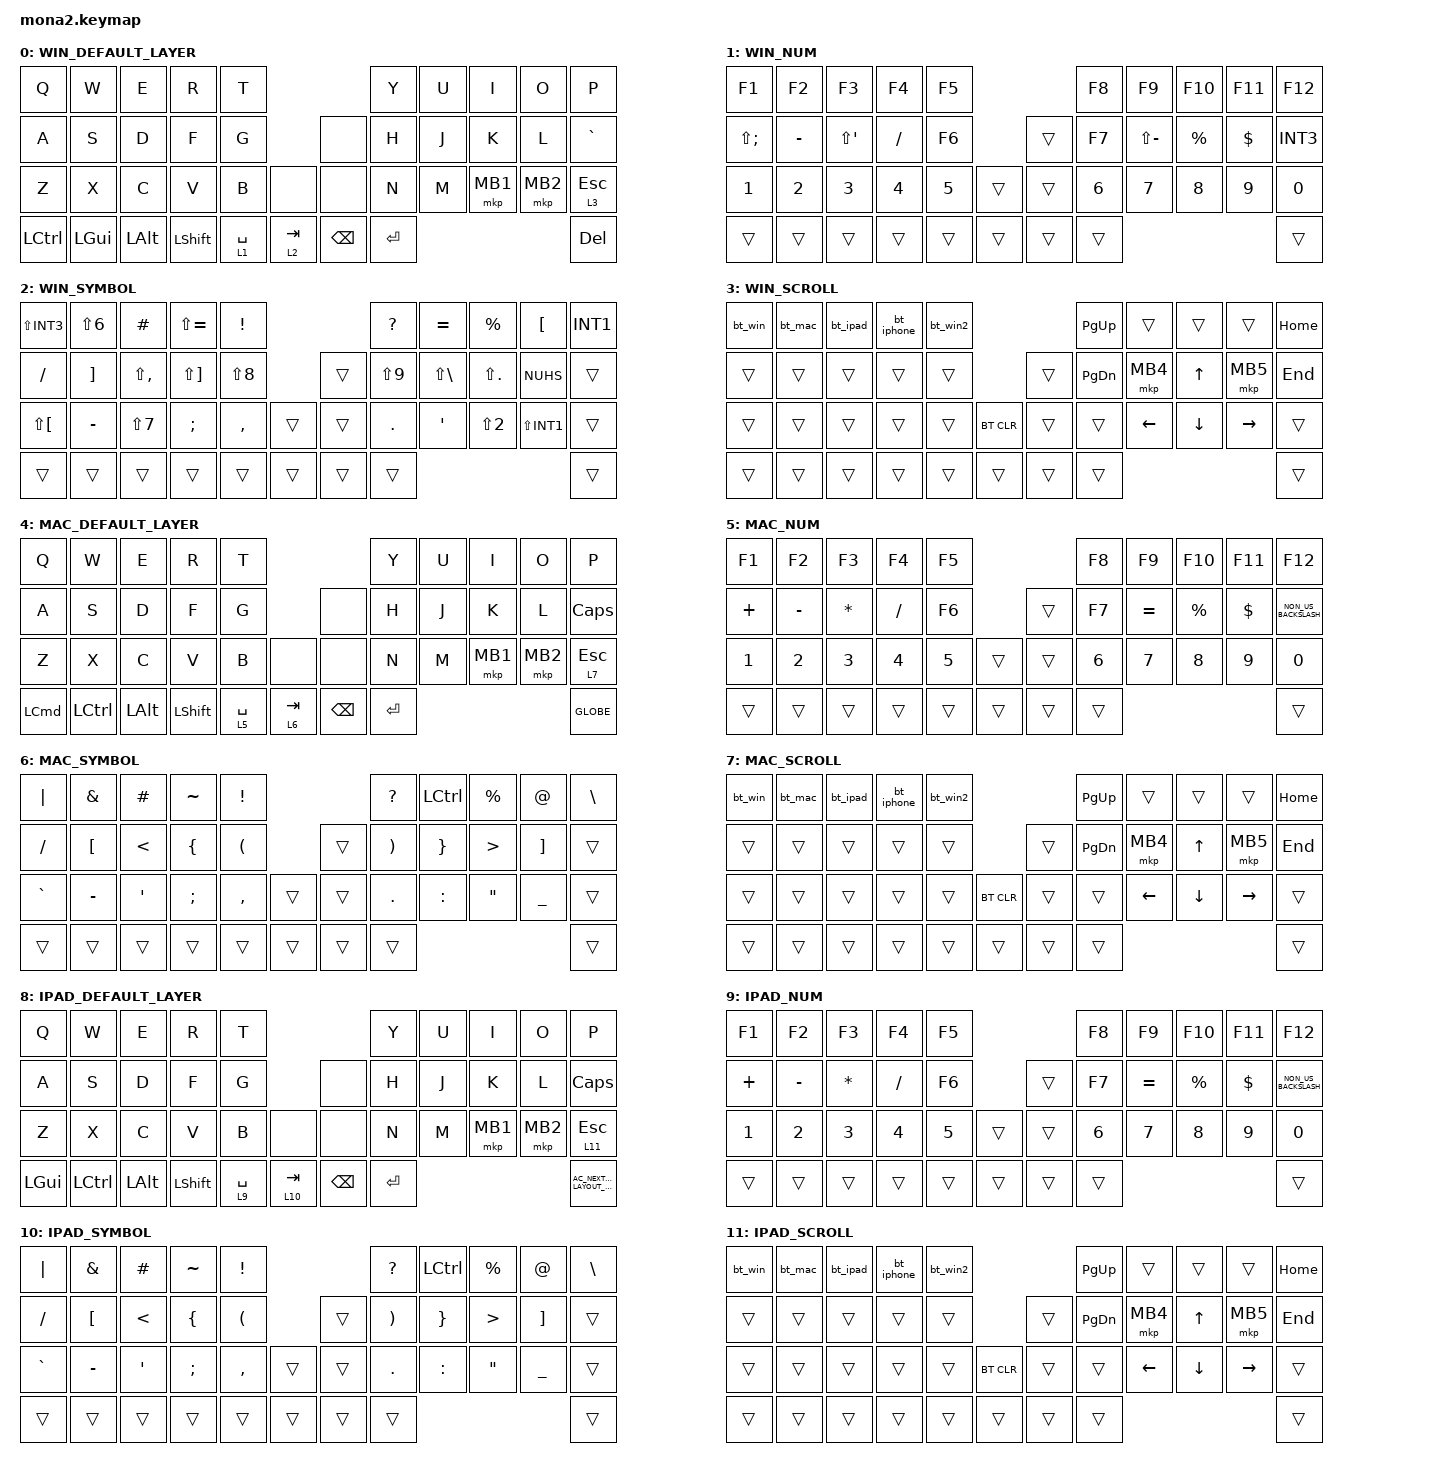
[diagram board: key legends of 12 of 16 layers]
#define ZMK_POINTING_DEFAULT_SCRL_VAL 300   // マウスホイール

#include <input/processors.dtsi>
#include <dt-bindings/zmk/input_transform.h>
#include <zephyr/dt-bindings/input/input-event-codes.h>
#include <behaviors.dtsi>
#include <dt-bindings/zmk/bt.h>
#include <dt-bindings/zmk/keys.h>
#include <dt-bindings/zmk/pointing.h>

#define MOUSE 0
#define SCROLL 3
#define NUM 2

&mt {
    flavor = "balanced";
    quick-tap-ms = <300>;
};

&lt {
    flavor = "balanced";
    quick-tap-ms = <300>;
};

/ {
    behaviors {
        scroll_up_down: behavior_sensor_rotate_mouse_wheel_up_down {
            compatible = "zmk,behavior-sensor-rotate";
            #sensor-binding-cells = <0>;
            bindings = <&msc SCRL_UP>, <&msc SCRL_DOWN>;

            tap-ms = <20>;
        };
    };

    combos { compatible = "zmk,combos"; };

    macros {
        bt_win: bt_win {
            compatible = "zmk,behavior-macro";
            #binding-cells = <0>;
            bindings = <&bt BT_SEL 0>, <&macro_wait_time 200>, <&to 0>;

            label = "BT_WIN";
        };

        bt_mac: bt_mac {
            compatible = "zmk,behavior-macro";
            #binding-cells = <0>;
            bindings = <&bt BT_SEL 1>, <&macro_wait_time 200>, <&to 4>;

            label = "BT_MAC";
        };

        bt_ipad: bt_ipad {
            compatible = "zmk,behavior-macro";
            #binding-cells = <0>;
            bindings = <&bt BT_SEL 2>, <&macro_wait_time 200>, <&to 8>;

            label = "BT_IPAD";
        };

        bt_iphone: bt_iphone {
            compatible = "zmk,behavior-macro";
            #binding-cells = <0>;
            bindings = <&bt BT_SEL 3>, <&macro_wait_time 200>, <&to 12>;

            label = "BT_IPHONE";
        };

        bt_win2: bt_win2 {
            compatible = "zmk,behavior-macro";
            #binding-cells = <0>;
            bindings = <&bt BT_SEL 4>, <&macro_wait_time 200>, <&to 0>;

            label = "BT_WIN2";
        };
    };

    keymap {
        compatible = "zmk,keymap";

        WIN_DEFAULT_LAYER {
            bindings = <
&kp Q      &kp W         &kp E         &kp R           &kp T                                    &kp Y      &kp U  &kp I     &kp O     &kp P
&kp A      &kp S         &kp D         &kp F           &kp G                     &none          &kp H      &kp J  &kp K     &kp L     &kp GRAVE
&kp Z      &kp X         &kp C         &kp V           &kp B        &none        &none          &kp N      &kp M  &mkp MB1  &mkp MB2  &lt 3 ESCAPE
&kp LCTRL  &kp LEFT_GUI  &kp LEFT_ALT  &kp LEFT_SHIFT  &lt 1 SPACE  &lt 2 TAB    &kp BACKSPACE  &kp ENTER                             &kp DELETE
            >;

            sensor-bindings = <&scroll_up_down>;
        };

        WIN_NUM {
            bindings = <
&kp F1        &kp F2        &kp F3        &kp F4        &kp F5                          &kp F8        &kp F9         &kp F10       &kp F11       &kp F12
&kp LS(SEMI)  &kp MINUS     &kp LS(SQT)   &kp SLASH     &kp F6                  &trans  &kp F7        &kp LS(MINUS)  &kp PERCENT   &kp DOLLAR    &kp INT3
&kp NUMBER_1  &kp NUMBER_2  &kp NUMBER_3  &kp NUMBER_4  &kp NUMBER_5  &trans    &trans  &kp NUMBER_6  &kp NUMBER_7   &kp NUMBER_8  &kp NUMBER_9  &kp NUMBER_0
&trans        &trans        &trans        &trans        &trans        &trans    &trans  &trans                                                   &trans
            >;
        };

        WIN_SYMBOL {
            bindings = <
&kp LS(INT3)  &kp LS(N6)  &kp POUND      &kp LS(EQUAL)  &kp EXCL                      &kp QMARK   &kp EQUAL          &kp PRCNT    &kp LBKT      &kp INT1
&kp SLASH     &kp RBKT    &kp LS(COMMA)  &kp LS(RBKT)   &kp LS(N8)            &trans  &kp LS(N9)  &kp LS(BACKSLASH)  &kp LS(DOT)  &kp NUHS      &trans
&kp LS(LBKT)  &kp MINUS   &kp LS(N7)     &kp SEMI       &kp COMMA   &trans    &trans  &kp DOT     &kp SQT            &kp LS(N2)   &kp LS(INT1)  &trans
&trans        &trans      &trans         &trans         &trans      &trans    &trans  &trans                                                    &trans
            >;
        };

        WIN_SCROLL {
            bindings = <
&bt_win  &bt_mac  &bt_ipad  &bt_iphone  &bt_win2                        &kp PAGE_UP    &trans          &trans          &trans           &kp HOME
&trans   &trans   &trans    &trans      &trans                  &trans  &kp PAGE_DOWN  &mkp MB4        &kp UP_ARROW    &mkp MB5         &kp END
&trans   &trans   &trans    &trans      &trans    &bt BT_CLR    &trans  &trans         &kp LEFT_ARROW  &kp DOWN_ARROW  &kp RIGHT_ARROW  &trans
&trans   &trans   &trans    &trans      &trans    &trans        &trans  &trans                                                          &trans
            >;
        };

        MAC_DEFAULT_LAYER {
            bindings = <
&kp Q             &kp W             &kp E         &kp R           &kp T                                    &kp Y      &kp U  &kp I     &kp O     &kp P
&kp A             &kp S             &kp D         &kp F           &kp G                     &none          &kp H      &kp J  &kp K     &kp L     &kp CAPS
&kp Z             &kp X             &kp C         &kp V           &kp B        &none        &none          &kp N      &kp M  &mkp MB1  &mkp MB2  &lt 7 ESCAPE
&kp LEFT_COMMAND  &kp LEFT_CONTROL  &kp LEFT_ALT  &kp LEFT_SHIFT  &lt 5 SPACE  &lt 6 TAB    &kp BACKSPACE  &kp ENTER                             &kp GLOBE
            >;

            sensor-bindings = <&scroll_up_down>;
        };

        MAC_NUM {
            bindings = <
&kp F1        &kp F2        &kp F3        &kp F4        &kp F5                          &kp F8        &kp F9        &kp F10       &kp F11       &kp F12
&kp PLUS      &kp MINUS     &kp ASTERISK  &kp SLASH     &kp F6                  &trans  &kp F7        &kp EQUAL     &kp PERCENT   &kp DOLLAR    &kp NON_US_BACKSLASH
&kp NUMBER_1  &kp NUMBER_2  &kp NUMBER_3  &kp NUMBER_4  &kp NUMBER_5  &trans    &trans  &kp NUMBER_6  &kp NUMBER_7  &kp NUMBER_8  &kp NUMBER_9  &kp NUMBER_0
&trans        &trans        &trans        &trans        &trans        &trans    &trans  &trans                                                  &trans
            >;
        };

        MAC_SYMBOL {
            bindings = <
&kp PIPE   &kp AMPERSAND     &kp HASH       &kp TILDE       &kp EXCL                                &kp QMARK              &kp LCTRL        &kp PRCNT          &kp AT_SIGN        &kp BACKSLASH
&kp SLASH  &kp LEFT_BRACKET  &kp LESS_THAN  &kp LEFT_BRACE  &kp LEFT_PARENTHESIS            &trans  &kp RIGHT_PARENTHESIS  &kp RIGHT_BRACE  &kp GREATER_THAN   &kp RIGHT_BRACKET  &trans
&kp GRAVE  &kp MINUS         &kp SQT        &kp SEMICOLON   &kp COMMA             &trans    &trans  &kp PERIOD             &kp COLON        &kp DOUBLE_QUOTES  &kp UNDERSCORE     &trans
&trans     &trans            &trans         &trans          &trans                &trans    &trans  &trans                                                                        &trans
            >;
        };

        MAC_SCROLL {
            bindings = <
&bt_win  &bt_mac  &bt_ipad  &bt_iphone  &bt_win2                        &kp PAGE_UP    &trans          &trans          &trans           &kp HOME
&trans   &trans   &trans    &trans      &trans                  &trans  &kp PAGE_DOWN  &mkp MB4        &kp UP_ARROW    &mkp MB5         &kp END
&trans   &trans   &trans    &trans      &trans    &bt BT_CLR    &trans  &trans         &kp LEFT_ARROW  &kp DOWN_ARROW  &kp RIGHT_ARROW  &trans
&trans   &trans   &trans    &trans      &trans    &trans        &trans  &trans                                                          &trans
            >;
        };

        IPAD_DEFAULT_LAYER {
            bindings = <
&kp Q         &kp W             &kp E         &kp R           &kp T                                     &kp Y      &kp U  &kp I     &kp O     &kp P
&kp A         &kp S             &kp D         &kp F           &kp G                      &none          &kp H      &kp J  &kp K     &kp L     &kp CAPS
&kp Z         &kp X             &kp C         &kp V           &kp B        &none         &none          &kp N      &kp M  &mkp MB1  &mkp MB2  &lt 11 ESCAPE
&kp LEFT_GUI  &kp LEFT_CONTROL  &kp LEFT_ALT  &kp LEFT_SHIFT  &lt 9 SPACE  &lt 10 TAB    &kp BACKSPACE  &kp ENTER                             &kp C_AC_NEXT_KEYBOARD_LAYOUT_SELECT
            >;

            sensor-bindings = <&scroll_up_down>;
        };

        IPAD_NUM {
            bindings = <
&kp F1        &kp F2        &kp F3        &kp F4        &kp F5                          &kp F8        &kp F9        &kp F10       &kp F11       &kp F12
&kp PLUS      &kp MINUS     &kp ASTERISK  &kp SLASH     &kp F6                  &trans  &kp F7        &kp EQUAL     &kp PERCENT   &kp DOLLAR    &kp NON_US_BACKSLASH
&kp NUMBER_1  &kp NUMBER_2  &kp NUMBER_3  &kp NUMBER_4  &kp NUMBER_5  &trans    &trans  &kp NUMBER_6  &kp NUMBER_7  &kp NUMBER_8  &kp NUMBER_9  &kp NUMBER_0
&trans        &trans        &trans        &trans        &trans        &trans    &trans  &trans                                                  &trans
            >;
        };

        IPAD_SYMBOL {
            bindings = <
&kp PIPE   &kp AMPERSAND     &kp HASH       &kp TILDE       &kp EXCL                                &kp QMARK              &kp LCTRL        &kp PRCNT          &kp AT_SIGN        &kp BACKSLASH
&kp SLASH  &kp LEFT_BRACKET  &kp LESS_THAN  &kp LEFT_BRACE  &kp LEFT_PARENTHESIS            &trans  &kp RIGHT_PARENTHESIS  &kp RIGHT_BRACE  &kp GREATER_THAN   &kp RIGHT_BRACKET  &trans
&kp GRAVE  &kp MINUS         &kp SQT        &kp SEMICOLON   &kp COMMA             &trans    &trans  &kp PERIOD             &kp COLON        &kp DOUBLE_QUOTES  &kp UNDERSCORE     &trans
&trans     &trans            &trans         &trans          &trans                &trans    &trans  &trans                                                                        &trans
            >;
        };

        IPAD_SCROLL {
            bindings = <
&bt_win  &bt_mac  &bt_ipad  &bt_iphone  &bt_win2                        &kp PAGE_UP    &trans          &trans          &trans           &kp HOME
&trans   &trans   &trans    &trans      &trans                  &trans  &kp PAGE_DOWN  &mkp MB4        &kp UP_ARROW    &mkp MB5         &kp END
&trans   &trans   &trans    &trans      &trans    &bt BT_CLR    &trans  &trans         &kp LEFT_ARROW  &kp DOWN_ARROW  &kp RIGHT_ARROW  &trans
&trans   &trans   &trans    &trans      &trans    &trans        &trans  &trans                                                          &trans
            >;
        };

        IPHONE_DEFAULT_LAYER {
            bindings = <
&kp Q         &kp W             &kp E         &kp R           &kp T                                      &kp Y      &kp U  &kp I     &kp O     &kp P
&kp A         &kp S             &kp D         &kp F           &kp G                       &none          &kp H      &kp J  &kp K     &kp L     &kp CAPS
&kp Z         &kp X             &kp C         &kp V           &kp B         &none         &none          &kp N      &kp M  &mkp MB1  &mkp MB2  &lt 15 ESCAPE
&kp LEFT_GUI  &kp LEFT_CONTROL  &kp LEFT_ALT  &kp LEFT_SHIFT  &lt 13 SPACE  &lt 14 TAB    &kp BACKSPACE  &kp ENTER                             &kp C_AC_NEXT_KEYBOARD_LAYOUT_SELECT
            >;

            sensor-bindings = <&scroll_up_down>;
        };

        IPHONE_NUM {
            bindings = <
&kp F1        &kp F2        &kp F3        &kp F4        &kp F5                          &kp F8        &kp F9        &kp F10       &kp F11       &kp F12
&kp PLUS      &kp MINUS     &kp ASTERISK  &kp SLASH     &kp F6                  &trans  &kp F7        &kp EQUAL     &kp PERCENT   &kp DOLLAR    &kp NON_US_BACKSLASH
&kp NUMBER_1  &kp NUMBER_2  &kp NUMBER_3  &kp NUMBER_4  &kp NUMBER_5  &trans    &trans  &kp NUMBER_6  &kp NUMBER_7  &kp NUMBER_8  &kp NUMBER_9  &kp NUMBER_0
&trans        &trans        &trans        &trans        &trans        &trans    &trans  &trans                                                  &trans
            >;
        };

        IPHONE_SYMBOL {
            bindings = <
&kp PIPE   &kp AMPERSAND     &kp HASH       &kp TILDE       &kp EXCL                                &kp QMARK              &kp LCTRL        &kp PRCNT          &kp AT_SIGN        &kp BACKSLASH
&kp SLASH  &kp LEFT_BRACKET  &kp LESS_THAN  &kp LEFT_BRACE  &kp LEFT_PARENTHESIS            &trans  &kp RIGHT_PARENTHESIS  &kp RIGHT_BRACE  &kp GREATER_THAN   &kp RIGHT_BRACKET  &trans
&kp GRAVE  &kp MINUS         &kp SQT        &kp SEMICOLON   &kp COMMA             &trans    &trans  &kp PERIOD             &kp COLON        &kp DOUBLE_QUOTES  &kp UNDERSCORE     &trans
&trans     &trans            &trans         &trans          &trans                &trans    &trans  &trans                                                                        &trans
            >;
        };

        IPHONE_SCROLL {
            bindings = <
&bt_win  &bt_mac  &bt_ipad  &bt_iphone  &bt_win2                        &kp PAGE_UP    &mkp LCLK       &mkp MB3        &mkp RCLK        &kp HOME
&trans   &trans   &trans    &trans      &trans                  &trans  &kp PAGE_DOWN  &mkp MB4        &kp UP_ARROW    &mkp MB5         &kp END
&trans   &trans   &trans    &trans      &trans    &bt BT_CLR    &trans  &trans         &kp LEFT_ARROW  &kp DOWN_ARROW  &kp RIGHT_ARROW  &trans
&trans   &trans   &trans    &trans      &trans    &trans        &trans  &trans                                                          &trans
            >;
        };
    };
};
